# boot register map
Vendor: Texas Instruments
Peripheral module from a debugger description file (folder Keystone).
Registers are 32-bit, read-write, no defined reset value unless marked. A register's access mark holds for its fields unless they carry their own. Offsets are as the file gives them; lines under a group give offsets from that group; [hi:lo] are bit positions; {n}, {i} and the like mark numbered series; 'fields as' and 'values as' point back to an identical list; <NAME> marks a mode.

## BOOT
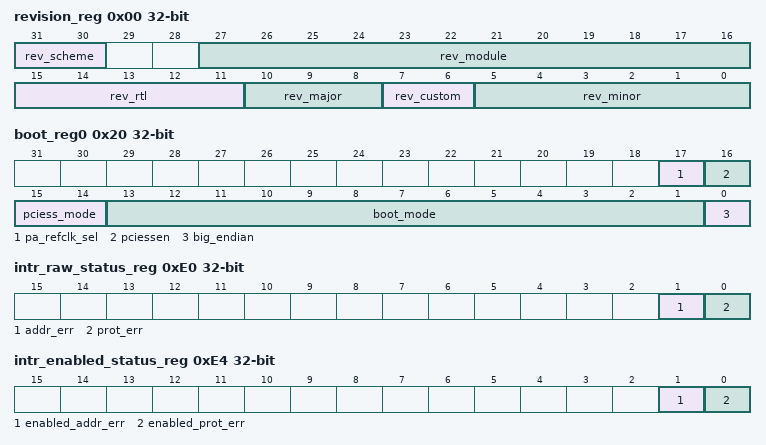
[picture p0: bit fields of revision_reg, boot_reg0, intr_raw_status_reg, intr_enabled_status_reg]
0x00 revision_reg
  [31:30] rev_scheme, [27:16] rev_module, [15:11] rev_rtl, [10:8] rev_major, [7:6] rev_custom, [5:0] rev_minor
{0x8+4i} die_id_reg{i} (i=0..3)
  [31:0] die_id{i}
0x18 device_id_reg0
  [31:0] device_id0
0x1C device_id_reg1
  [31:0] device_id1
0x20 boot_reg0
  [17] pa_refclk_sel, [16] pciessen, [15:14] pciess_mode, [13:1] boot_mode, [0] big_endian
0x38 kick_reg0
  [31:0] kick0
0x3C kick_reg1
  [31:0] kick1
0x40 bootaddr_gem_reg access not given — (1 of 4, stride 4)
0xE0 intr_raw_status_reg
  [1] addr_err, [0] prot_err
0xE4 intr_enabled_status_reg
  [1] enabled_addr_err, [0] enabled_prot_err
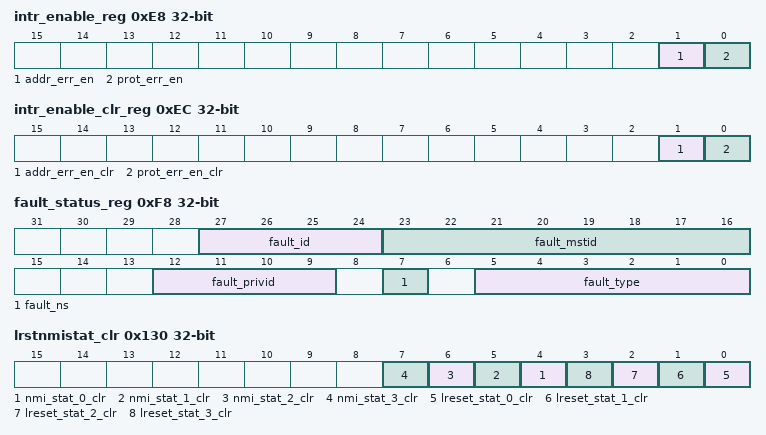
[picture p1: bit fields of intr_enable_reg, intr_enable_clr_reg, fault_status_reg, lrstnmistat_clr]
0xE8 intr_enable_reg
  [1] addr_err_en, [0] prot_err_en
0xEC intr_enable_clr_reg
  [1] addr_err_en_clr, [0] prot_err_en_clr
0xF0 eoi_reg
  [7:0] eoi_vector
0xF4 fault_address_reg
  [31:0] fault_addr
0xF8 fault_status_reg
  [27:24] fault_id, [23:16] fault_mstid, [12:9] fault_privid, [7] fault_ns, [5:0] fault_type
0xFC fault_clear_reg
  [0] fault_clear
0x110 emac_id1
0x114 emac_id2
0x130 lrstnmistat_clr
  [n+4] nmi_stat_{n}_clr (n=0..3), [n] lreset_stat_{n}_clr (n=0..3)
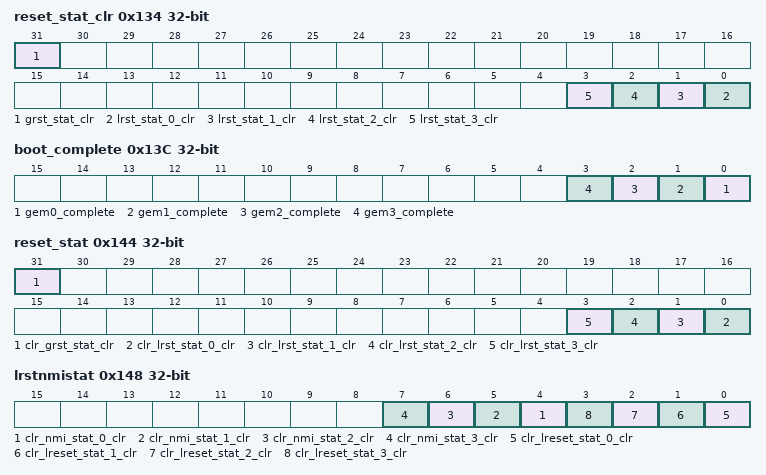
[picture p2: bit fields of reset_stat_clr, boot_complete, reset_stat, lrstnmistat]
0x134 reset_stat_clr
  [31] grst_stat_clr, [n] lrst_stat_{n}_clr (n=0..3)
0x13C boot_complete
  [n] gem{n}_complete (n=0..3)
0x140 boot_progress
0x144 reset_stat
  [31] clr_grst_stat_clr, [n] clr_lrst_stat_{n}_clr (n=0..3)
0x148 lrstnmistat
  [n+4] clr_nmi_stat_{n}_clr (n=0..3), [n] clr_lreset_stat_{n}_clr (n=0..3)
0x14C devcfg
  [0] sysclkouten
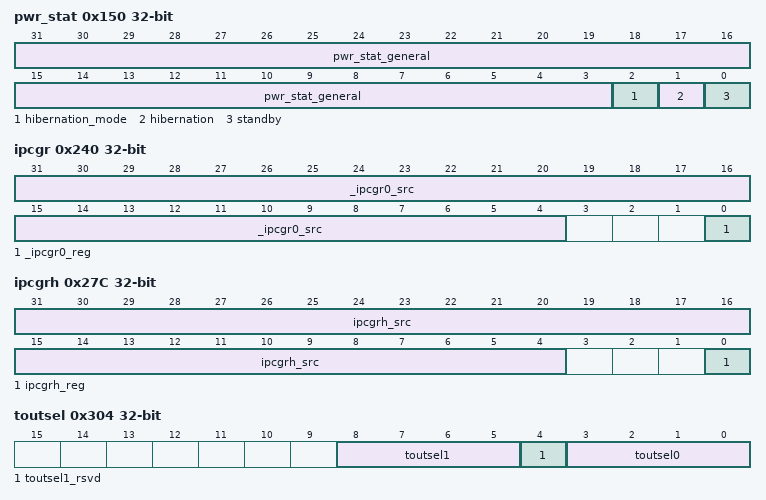
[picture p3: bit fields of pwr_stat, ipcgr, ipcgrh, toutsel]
0x150 pwr_stat
  [31:3] pwr_stat_general, [2] hibernation_mode, [1] hibernation, [0] standby
0x154 sts_srio
  [28:0] sts_srio
0x158 sts_sgmii
  [12:0] sts_sgmii
0x15C sts_pcie
  [12:0] sts_pcie
0x160 sts_vusr
  [28:0] sts_vusr
0x164 sts_aif2_b8
  [28:0] sts_aif2_b8
0x168 sts_aif2_b4
  [14:0] sts_aif2_b4
0x180 class0_efuse_reg
{0x190+4i} efuse_reg{i} (i=0..15)
0x200 nmigr — (1 of 4, stride 4)
  [0] 0_nmigr_0_reg
0x240 ipcgr — (1 of 4, stride 4)
  [31:4] _ipcgr0_src, [0] _ipcgr0_reg
0x27C ipcgrh
  [31:4] ipcgrh_src, [0] ipcgrh_reg
0x280 ipcar — (1 of 4, stride 4)
  [31:4] _ipcgr0_src_clr
0x2BC ipcarh
  [31:4] ipcgrh_src_clr
0x300 tinpsel
  [15:0] tinpsel
0x304 toutsel
  [8:5] toutsel1, [4] toutsel1_rsvd, [3:0] toutsel0
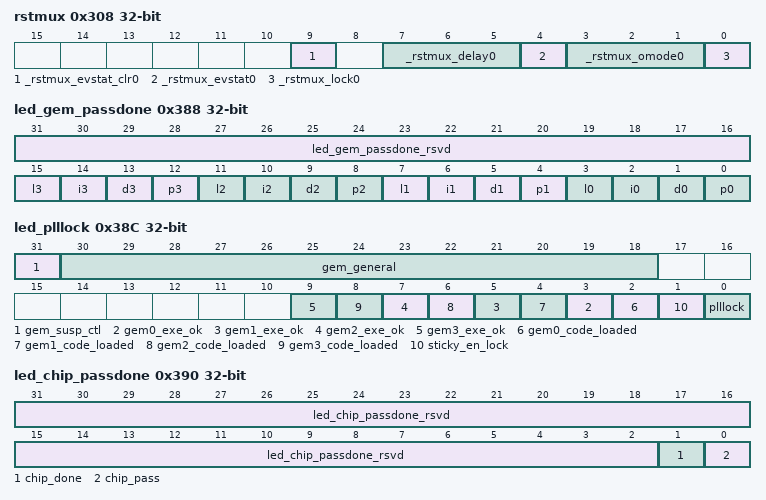
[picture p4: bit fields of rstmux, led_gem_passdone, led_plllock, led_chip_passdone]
0x308 rstmux — (1 of 4, stride 4)
  [9] _rstmux_evstat_clr0, [7:5] _rstmux_delay0, [4] _rstmux_evstat0, [3:1] _rstmux_omode0, [0] _rstmux_lock0
0x328 core_pll_ctl0
0x32C core_pll_ctl1
0x330 ddr3_pll_ctl0
0x334 ddr3_pll_ctl1
0x338 pa_pll_ctl0
0x33C pa_pll_ctl1
0x340 sgmii_cfgpll
  [15:0] sgmii_cfgpll
0x344 sgmii_cfgrx0
  [31:0] sgmii_rxcfg0
0x348 sgmii_cfgtx0
  [31:0] sgmii_txcfg0
0x34C sgmii_cfgrx1
  [31:0] sgmii_rxcfg1
0x350 sgmii_cfgtx1
  [31:0] sgmii_txcfg1
0x354 sgmii_rsvd
0x358 pcie_cfgpll
  [15:0] pcie_cfgpll
0x35C pcie_serdes_rsvd
0x360 srio_serdes_cfgpll
{0x364+8i} srio_serdes_cfgrx{i} (i=0..3)
{0x368+8i} srio_serdes_cfgtx{i} (i=0..3)
0x384 srio_serdes_rsvd
0x388 led_gem_passdone
  [31:16] led_gem_passdone_rsvd, [4n+3] l{n} (n=0..3), [4n+2] i{n} (n=0..3), [4n+1] d{n} (n=0..3), [4n] p{n} (n=0..3)
0x38C led_plllock
  [31] gem_susp_ctl, [30:18] gem_general, [2n+3] gem{n}_exe_ok (n=0..3), [2n+2] gem{n}_code_loaded (n=0..3), [1] sticky_en_lock, [0] plllock
0x390 led_chip_passdone
  [31:2] led_chip_passdone_rsvd, [1] chip_done, [0] chip_pass
0x394 tdiode
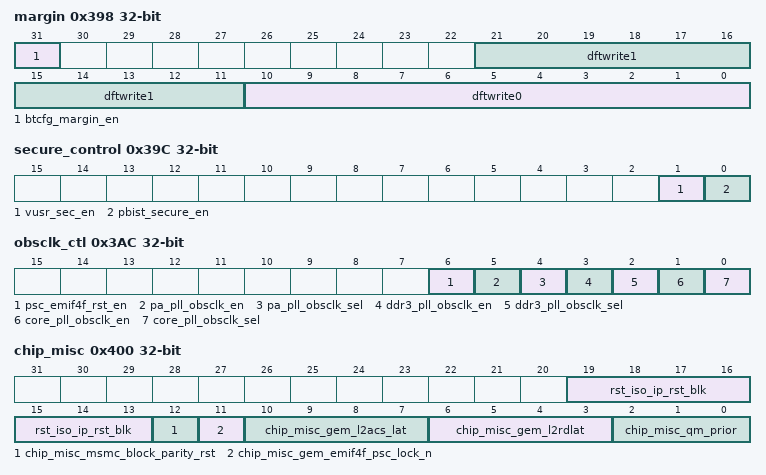
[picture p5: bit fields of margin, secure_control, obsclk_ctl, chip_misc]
0x398 margin
  [31] btcfg_margin_en, [21:11] dftwrite1, [10:0] dftwrite0
0x39C secure_control
  [1] vusr_sec_en, [0] pbist_secure_en
0x3A4 efuse_secrom_chksum0
0x3A8 efuse_secrom_chksum1
0x3AC obsclk_ctl
  [6] psc_emif4f_rst_en, [5] pa_pll_obsclk_en, [4] pa_pll_obsclk_sel, [3] ddr3_pll_obsclk_en, [2] ddr3_pll_obsclk_sel, [1] core_pll_obsclk_en, [0] core_pll_obsclk_sel
0x3B0 aif_serdes_rsvd
0x3B4 vusr_cfgpll
  [15:0] vusr_cfgpll
{0x3B8+8i} vusr_cfgrx{i} (i=0..3)
{0x3BC+8i} vusr_cfgtx{i} (i=0..3)
0x3D8 vusr_serdes_rsvd
0x3DC led_gpio_clr
  [31:0] led_gpio_src_clr
0x3E0 led_gpio
  [31:0] clr_led_gpio_src_clr
{0x3F0+4i} efuse_rsvd{i} (i=0..3)
0x400 chip_misc
  [19:13] rst_iso_ip_rst_blk, [12] chip_misc_msmc_block_parity_rst, [11] chip_misc_gem_emif4f_psc_lock_n, [10:7] chip_misc_gem_l2acs_lat, [6:3] chip_misc_gem_l2rdlat, [2:0] chip_misc_qm_prior
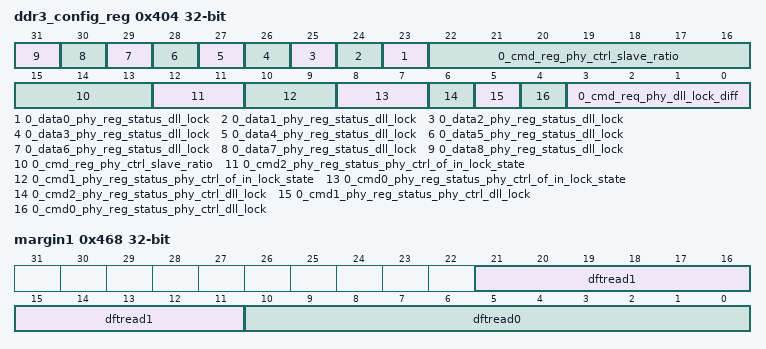
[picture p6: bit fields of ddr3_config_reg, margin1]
0x404 ddr3_config_reg — (1 of 25, stride 4)
  [n+23] 0_data{n}_phy_reg_status_dll_lock (n=0..8), [22:13] 0_cmd_reg_phy_ctrl_slave_ratio, [12:11] 0_cmd2_phy_reg_status_phy_ctrl_of_in_lock_state, [10:9] 0_cmd1_phy_reg_status_phy_ctrl_of_in_lock_state, [8:7] 0_cmd0_phy_reg_status_phy_ctrl_of_in_lock_state, [6] 0_cmd2_phy_reg_status_phy_ctrl_dll_lock, [5] 0_cmd1_phy_reg_status_phy_ctrl_dll_lock, [4] 0_cmd0_phy_reg_status_phy_ctrl_dll_lock, [3:0] 0_cmd_req_phy_dll_lock_diff
0x468 margin1
  [21:11] dftread1, [10:0] dftread0
0x1FFF end_point
